AUTOSAR XML (schema 314)
package /ComponentType
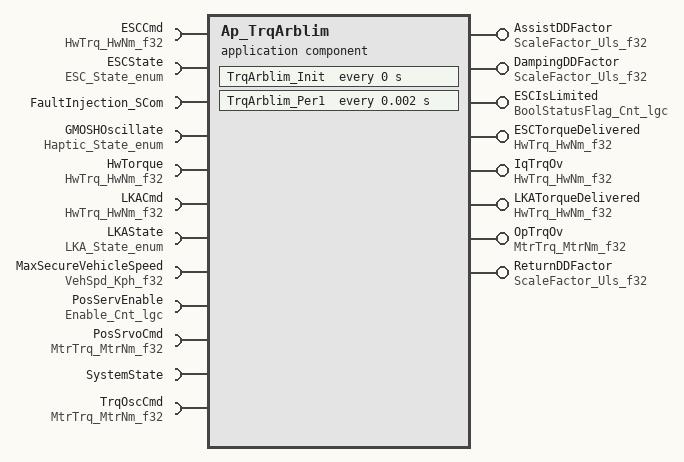
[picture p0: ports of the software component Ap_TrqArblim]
  application software component type Ap_TrqArblim
    8 x provide port:
      AssistDDFactor: unqueued-sender-com-spec{data-element=Uls_f32, can-invalidate=false, init-value=D_ONE_ULS_F32}, provided-interface=ScaleFactor_Uls_f32
      DampingDDFactor: unqueued-sender-com-spec{data-element=Uls_f32, can-invalidate=false, init-value=D_ONE_ULS_F32}, provided-interface=ScaleFactor_Uls_f32
      ESCIsLimited: unqueued-sender-com-spec{data-element=Cnt_lgc, can-invalidate=false, init-value=D_FALSE_CNT_LGC}, provided-interface=BoolStatusFlag_Cnt_lgc
      ESCTorqueDelivered: unqueued-sender-com-spec{data-element=HwNm_f32, can-invalidate=false, init-value=D_ZERO_ULS_F32}, provided-interface=HwTrq_HwNm_f32
      IqTrqOv: unqueued-sender-com-spec{data-element=HwNm_f32, can-invalidate=false, init-value=D_ZERO_ULS_F32}, provided-interface=HwTrq_HwNm_f32
      LKATorqueDelivered: unqueued-sender-com-spec{data-element=HwNm_f32, can-invalidate=false, init-value=D_ZERO_ULS_F32}, provided-interface=HwTrq_HwNm_f32
      OpTrqOv: unqueued-sender-com-spec{data-element=MtrNm_f32, can-invalidate=false, init-value=D_ZERO_ULS_F32}, provided-interface=MtrTrq_MtrNm_f32
      ReturnDDFactor: unqueued-sender-com-spec{data-element=Uls_f32, can-invalidate=false, init-value=D_ONE_ULS_F32}, provided-interface=ScaleFactor_Uls_f32
    12 x require port:
      ESCCmd: unqueued-receiver-com-spec{data-element=HwNm_f32, init-value=D_ZERO_ULS_F32}, required-interface=HwTrq_HwNm_f32
      ESCState: unqueued-receiver-com-spec{data-element=State_enum, init-value=D_ESCSTATEINIT_CNT_U08}, required-interface=ESC_State_enum
      FaultInjection_SCom: client-com-spec=FltInjection, required-interface=FaultInjection_SCom
      GMOSHOscillate: unqueued-receiver-com-spec{data-element=State_enum, init-value=D_HAPTICSTATEINIT_CNT_U08}, required-interface=Haptic_State_enum
      HwTorque: unqueued-receiver-com-spec{data-element=HwNm_f32, init-value=D_ZERO_ULS_F32}, required-interface=HwTrq_HwNm_f32
      LKACmd: unqueued-receiver-com-spec{data-element=HwNm_f32, init-value=D_ZERO_ULS_F32}, required-interface=HwTrq_HwNm_f32
      LKAState: unqueued-receiver-com-spec{data-element=State_enum, init-value=D_LKASTATEINIT_CNT_U08}, required-interface=LKA_State_enum
      MaxSecureVehicleSpeed: unqueued-receiver-com-spec{data-element=Kph_f32, init-value=D_ZERO_ULS_F32}, required-interface=VehSpd_Kph_f32
      PosServEnable: unqueued-receiver-com-spec{data-element=Cnt_lgc, init-value=D_FALSE_CNT_LGC}, required-interface=Enable_Cnt_lgc
      PosSrvoCmd: unqueued-receiver-com-spec{data-element=MtrNm_f32, init-value=D_ZERO_ULS_F32}, required-interface=MtrTrq_MtrNm_f32
      SystemState: required-interface=SystemState
      TrqOscCmd: unqueued-receiver-com-spec{data-element=MtrNm_f32, init-value=D_ZERO_ULS_F32}, required-interface=MtrTrq_MtrNm_f32
  internal behavior Ap_TrqArblim_InternalBehavior: component=Ap_TrqArblim
    timing event TrqArblim_InitEvent: start-on-event=TrqArblim_Init, period=0
    timing event TMT_TrqArblim_Per1: mode-dependency=dependent-on-mode=[SystemState.Mode.DISABLE, SystemState.Mode.OFF, SystemState.Mode.WARMINIT], start-on-event=TrqArblim_Per1, period=0.002
    port-api-options:
      enable-take-address=false, indirect-api=false, port=AssistDDFactor
      enable-take-address=false, indirect-api=false, port=DampingDDFactor
      enable-take-address=false, indirect-api=false, port=ESCCmd
      enable-take-address=false, indirect-api=false, port=ESCIsLimited
      enable-take-address=false, indirect-api=false, port=ESCState
      enable-take-address=false, indirect-api=false, port=ESCTorqueDelivered
      enable-take-address=false, indirect-api=false, port=FaultInjection_SCom
      enable-take-address=false, indirect-api=false, port=GMOSHOscillate
      enable-take-address=false, indirect-api=false, port=HwTorque
      enable-take-address=false, indirect-api=false, port=IqTrqOv
      enable-take-address=false, indirect-api=false, port=LKACmd
      enable-take-address=false, indirect-api=false, port=LKAState
      enable-take-address=false, indirect-api=false, port=LKATorqueDelivered
      enable-take-address=false, indirect-api=false, port=MaxSecureVehicleSpeed
      enable-take-address=false, indirect-api=false, port=OpTrqOv
      enable-take-address=false, indirect-api=false, port=PosServEnable
      enable-take-address=false, indirect-api=false, port=PosSrvoCmd
      enable-take-address=false, indirect-api=false, port=ReturnDDFactor
      enable-take-address=false, indirect-api=false, port=SystemState
      enable-take-address=false, indirect-api=false, port=TrqOscCmd
    runnable TrqArblim_Init
    runnable TrqArblim_Per1
      10 x data read access:
        READ_ESCCmd_HwNm_f32: data-element=ESCCmd.HwNm_f32
        READ_ESCState_State_enum: data-element=ESCState.State_enum
        READ_GMOSHOscillate_State_enum: data-element=GMOSHOscillate.State_enum
        READ_HwTorque_HwNm_f32: data-element=HwTorque.HwNm_f32
        READ_LKACmd_HwNm_f32: data-element=LKACmd.HwNm_f32
        READ_LKAState_State_enum: data-element=LKAState.State_enum
        READ_MaxSecureVehicleSpeed_Kph_f32: data-element=MaxSecureVehicleSpeed.Kph_f32
        READ_PosServEnable_Cnt_lgc: data-element=PosServEnable.Cnt_lgc
        READ_PosSrvoCmd_MtrNm_f32: data-element=PosSrvoCmd.MtrNm_f32
        READ_TrqOscCmd_MtrNm_f32: data-element=TrqOscCmd.MtrNm_f32
      8 x data write access:
        WRITE_AssistDDFactor_Uls_f32: data-element=AssistDDFactor.Uls_f32
        WRITE_DampingDDFactor_Uls_f32: data-element=DampingDDFactor.Uls_f32
        WRITE_ESCIsLimited_Cnt_lgc: data-element=ESCIsLimited.Cnt_lgc
        WRITE_ESCTorqueDelivered_HwNm_f32: data-element=ESCTorqueDelivered.HwNm_f32
        WRITE_IqTrqOv_HwNm_f32: data-element=IqTrqOv.HwNm_f32
        WRITE_LKATorqueDelivered_HwNm_f32: data-element=LKATorqueDelivered.HwNm_f32
        WRITE_OpTrqOv_MtrNm_f32: data-element=OpTrqOv.MtrNm_f32
        WRITE_ReturnDDFactor_Uls_f32: data-element=ReturnDDFactor.Uls_f32
      sync call SC_FaultInjection_SCom_FltInjection: operation=FaultInjection_SCom.FltInjection, timeout=0
  swc implementation Ap_TrqArblim_Implementation: behavior=Ap_TrqArblim_InternalBehavior
    code-descriptors:
      code Code: type=SRC
